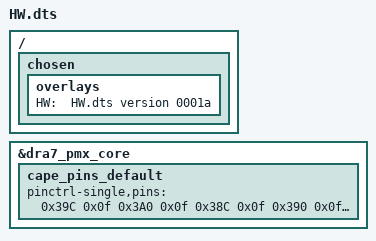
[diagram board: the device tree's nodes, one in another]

/dts-v1/;
/plugin/;

/ {
    fragment@0 {
        target-path="/";
        __overlay__ {
            chosen {
                overlays {
                    HW = " HW.dts version 0001a";
                };
            };
        };
    };

    fragment@1 {
        target = <&dra7_pmx_core>;
        __overlay__ {
            cape_pins_default {
                pinctrl-single,pins = <
                /* /header/ offset mode

                /*P8_03*/ 0x39C  0x0f
                /*P8_04*/ 0x3A0  0x0f
                /*P8_05*/ 0x38C  0x0f
                /*P8_06*/ 0x390  0x0f
                /*P8_07*/ 0x2EC  0x0f
                /*P8_08*/ 0x2F0  0x0f
                /*P8_09*/ 0x298  0x0f

                /*P8_10*/ 0x2E8  0x0f
                /*P8_11*/ 0x110  0x0f /*P9_11A*/ 0x32C 0x0f
                                      /*P9_11B*/ 0x220 0x0f
                /*P8_12*/ 0x10C  0x0f /*P9_12*/  0x2AC 0x0f
                /*P8_13*/ 0x190  0x0f /*P9_13A*/ 0x330 0x0f
                                      /*P9_13B*/ 0x280 0x0f
                /*P8_14*/ 0x198  0x0f /*P9_14*/  0x1AC 0x0f
                /*P8_15A*/ 0x170 0x0f /*P9_15A*/ 0x114 0x0f
                /*P8_15B*/ 0x1B4 0x0f /*P9_15B*/
                /*P8_16*/ 0x1BC  0x0f /*P9_16*/  0x1B0 0x0f
                /*P8_17*/ 0x224  0x0f /*P9_17A*/ 0x3CC 0x0f
                                      /*P9_17B*/ 0x2B8 0x0f
                /*P8_18*/ 0x188  0x0f /*P9_18A*/ 0x3C8 0x0f
                                      /*P9_18B*/ 0x2B4 0x0f
                /*P8_19*/ 0x18C  0x0f /*P9_19A*/ 0x040 0x0f
                                      /*P9_19B*/ 0x17C 0x0f

                /*P8_20*/ 0x380  0x0f /*P9_20A*/ 0x044 0x0f
                                      /*P9_20B*/ 0x178 0x0f
                /*P8_21*/ 0x37C  0x0f /*P9_21A*/ 0x0F0 0x0f
                                      /*P9_21B*/ 0x3C4 0x0f
                /*P8_22*/ 0x398  0x0f /*P9_22A*/ 0x29C 0x0f
                                      /*P9_22B*/ 0x3C0 0x0f
                /*P8_23*/ 0x394  0x0f /*P9_23*/  0x3B4 0x0f
                /*P8_24*/ 0x388  0x0f /*P9_24*/  0x28C 0x0f
                /*P8_25*/ 0x384  0x0f /*P9_25*/  0x294 0x0f
                /*P8_26*/ 0x1B8  0x0f /*P9_26A*/ 0x288 0x0f
                                      /*P9_26B*/ 0x144 0x0f
                /*P8_27A*/ 0x1D8 0x0f /*P9_27A*/ 0x1A0 0x0f
                /*P8_27B*/ 0x228 0x0f /*P9_27B*/ 0x2B0 0x0f
                /*P8_28A*/ 0x1C8 0x0f /*P9_28A*/ 0x2E0 0x0f
                /*P8_28B*/ 0x22C 0x0f
                /*P8_29A*/ 0x1D4 0x0f /*P9_29A*/ 0x2D8 0x0f
                /*P8_29B*/ 0x230 0x0f /*P9_29B*/ 0x2A8 0x0f

                /*P8_30A*/ 0x1CC 0x0f /*P9_30A*/ 0x2DC 0x0f
                /*P8_30B*/ 0x234 0x0f 
                /*P8_31A*/ 0x214 0x0f /*P9_31A*/ 0x2D4 0x0f
                /*P8_31B*/ 0x33C 0x0f /*P9_31B*/ 0x2A4 0x0f
                /*P8_32A*/ 0x218 0x0f
                /*P8_32B*/ 0x340 0x0f
                /*P8_33A*/ 0x210 0x0f
                /*P8_33B*/ 0x0E8 0x0f
                /*P8_34A*/ 0x208 0x0f
                /*P8_34B*/ 0x164 0x0f
                /*P8_35A*/ 0x20C 0x0f
                /*P8_35B*/ 0x0E4 0x0f
                /*P8_36A*/ 0x204 0x0f
                /*P8_36B*/ 0x168 0x0f
                /*P8_37A*/ 0x1FC 0x0f
                /*P8_37B*/ 0x338 0x0f
                /*P8_38A*/ 0x200 0x0f
                /*P8_38B*/ 0x334 0x0f
                /*P8_39*/ 0x1F4  0x0f

                /*P8_40*/ 0x1F8  0x0f
                /*P8_41*/ 0x1EC  0x0f /*P9_41A*/ 0x2A0  0x0f
                                      /*P9_41B*/ 0x2E4  0x0f
                /*P8_42*/ 0x1F0  0x0f /*P9_42A*/ 0x180  0x0f
                                      /*P9_42B*/ 0x19C  0x0f
                /*P8_43*/ 0x1E4  0x0f
                /*P8_44*/ 0x1E8  0x0f
                /*P8_45A*/ 0x1DC 0x0f
                /*P8_45B*/ 0x21C 0x0f
                /*P8_46A*/ 0x1E0 0x0f
                /*P8_46B*/ 0x238 0x0f
                >;
            };
        };
    };
};
